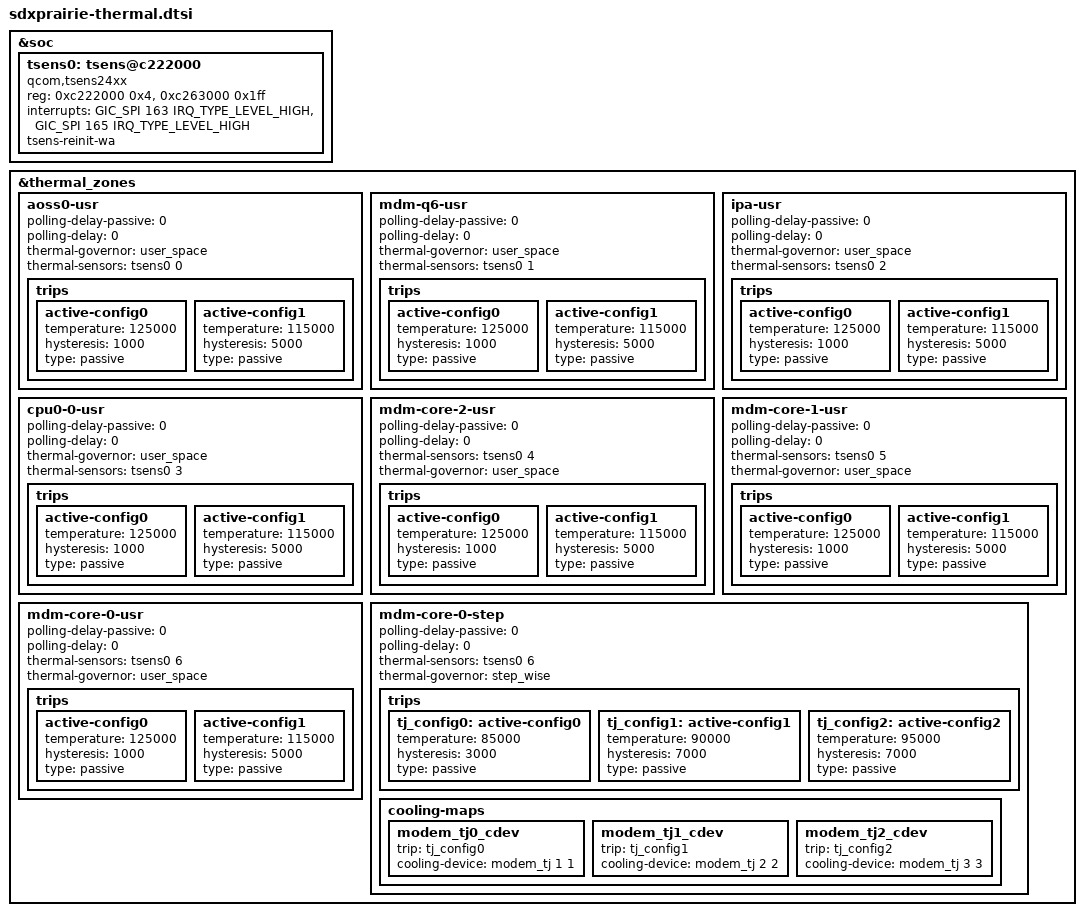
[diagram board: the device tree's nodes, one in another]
#include <dt-bindings/thermal/thermal.h>
#include <dt-bindings/thermal/thermal_qti.h>
#include "sdxprairie-thermal-common.dtsi"


&soc {
	tsens0: tsens@c222000 {
		compatible = "qcom,tsens24xx";
		reg = <0xc222000 0x4>,
			<0xc263000 0x1ff>;
		reg-names = "tsens_srot_physical",
				"tsens_tm_physical";
		interrupts = <GIC_SPI 163 IRQ_TYPE_LEVEL_HIGH>,
						<GIC_SPI 165 IRQ_TYPE_LEVEL_HIGH>;
		interrupt-names = "tsens-upper-lower", "tsens-critical";
		tsens-reinit-wa;
		#thermal-sensor-cells = <1>;
	};
};

&thermal_zones {
	aoss0-usr {
		polling-delay-passive = <0>;
		polling-delay = <0>;
		thermal-governor = "user_space";
		thermal-sensors = <&tsens0 0>;
		trips {
			active-config0 {
				temperature = <125000>;
				hysteresis = <1000>;
				type = "passive";
			};

			active-config1 {
				temperature = <115000>;
				hysteresis = <5000>;
				type = "passive";
			};
		};
	};

	mdm-q6-usr {
		polling-delay-passive = <0>;
		polling-delay = <0>;
		thermal-governor = "user_space";
		thermal-sensors = <&tsens0 1>;
		trips {
			active-config0 {
				temperature = <125000>;
				hysteresis = <1000>;
				type = "passive";
			};

			active-config1 {
				temperature = <115000>;
				hysteresis = <5000>;
				type = "passive";
			};
		};
	};

	ipa-usr {
		polling-delay-passive = <0>;
		polling-delay = <0>;
		thermal-governor = "user_space";
		thermal-sensors = <&tsens0 2>;
		trips {
			active-config0 {
				temperature = <125000>;
				hysteresis = <1000>;
				type = "passive";
			};

			active-config1 {
				temperature = <115000>;
				hysteresis = <5000>;
				type = "passive";
			};
		};
	};

	cpu0-0-usr {
		polling-delay-passive = <0>;
		polling-delay = <0>;
		thermal-governor = "user_space";
		thermal-sensors = <&tsens0 3>;
		trips {
			active-config0 {
				temperature = <125000>;
				hysteresis = <1000>;
				type = "passive";
			};

			active-config1 {
				temperature = <115000>;
				hysteresis = <5000>;
				type = "passive";
			};
		};
	};

	mdm-core-2-usr {
		polling-delay-passive = <0>;
		polling-delay = <0>;
		thermal-sensors = <&tsens0 4>;
		thermal-governor = "user_space";
		trips {
			active-config0 {
				temperature = <125000>;
				hysteresis = <1000>;
				type = "passive";
			};

			active-config1 {
				temperature = <115000>;
				hysteresis = <5000>;
				type = "passive";
			};
		};
	};

	mdm-core-1-usr {
		polling-delay-passive = <0>;
		polling-delay = <0>;
		thermal-sensors = <&tsens0 5>;
		thermal-governor = "user_space";
		trips {
			active-config0 {
				temperature = <125000>;
				hysteresis = <1000>;
				type = "passive";
			};

			active-config1 {
				temperature = <115000>;
				hysteresis = <5000>;
				type = "passive";
			};
		};
	};

	mdm-core-0-usr {
		polling-delay-passive = <0>;
		polling-delay = <0>;
		thermal-sensors = <&tsens0 6>;
		thermal-governor = "user_space";
		trips {
			active-config0 {
				temperature = <125000>;
				hysteresis = <1000>;
				type = "passive";
			};

			active-config1 {
				temperature = <115000>;
				hysteresis = <5000>;
				type = "passive";
			};
		};
	};

	mdm-core-0-step {
		polling-delay-passive = <0>;
		polling-delay = <0>;
		thermal-sensors = <&tsens0 6>;
		thermal-governor = "step_wise";
		trips {
			tj_config0: active-config0 {
				temperature = <85000>;
				hysteresis = <3000>;
				type = "passive";
			};

			tj_config1: active-config1 {
				temperature = <90000>;
				hysteresis = <7000>;
				type = "passive";
			};

			tj_config2: active-config2 {
				temperature = <95000>;
				hysteresis = <7000>;
				type = "passive";
			};
		};

		cooling-maps {
			modem_tj0_cdev {
				trip = <&tj_config0>;
				cooling-device = <&modem_tj 1 1>;
			};

			modem_tj1_cdev {
				trip = <&tj_config1>;
				cooling-device = <&modem_tj 2 2>;
			};

			modem_tj2_cdev {
				trip = <&tj_config2>;
				cooling-device = <&modem_tj 3 3>;
			};
		};
	};
};
